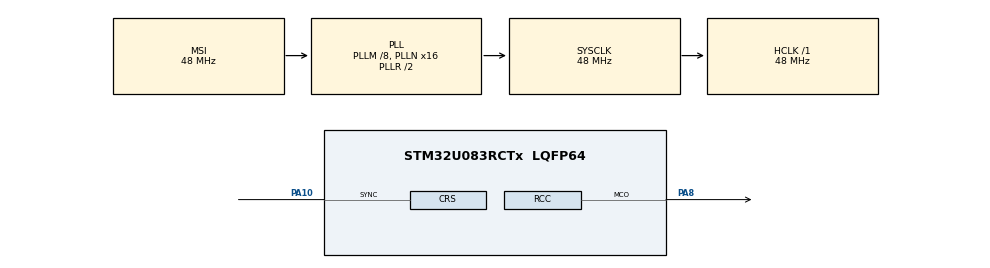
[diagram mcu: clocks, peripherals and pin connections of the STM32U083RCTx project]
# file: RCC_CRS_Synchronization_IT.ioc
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Mcu.Family=STM32U0
Mcu.Name=STM32U083RCTx
Mcu.Package=LQFP64
NVIC.PriorityGroup=NVIC_PRIORITYGROUP_2
PA10.Mode=CRS SYNC Source GPIO
PA10.Signal=CRS_SYNC
PA8.GPIO_Speed=GPIO_SPEED_FREQ_HIGH
PA8.Mode=Clock-out
PA8.Signal=RCC_MCO
PC14-OSC32_IN.Mode=LSE-External-Oscillator
PC14-OSC32_IN.Signal=RCC_OSC32_IN
PC15-OSC32_OUT.Mode=LSE-External-Oscillator
PC15-OSC32_OUT.Signal=RCC_OSC32_OUT
ProjectManager.HeapSize=0x200
ProjectManager.StackSize=0x400
ProjectManager.TargetToolchain=EWARM V9.20
RCC.ADCFreq_Value=48000000
RCC.AHBFreq_Value=48000000
RCC.CortexFreq_Value=48000000
RCC.HCLKFreq_Value=48000000
RCC.HSE_VALUE=4000000
RCC.HSI48_VALUE=48000000
RCC.HSI_VALUE=16000000
RCC.MSIClockRangeVal=RCC_MSIRANGE_11
RCC.MSI_VALUE=48000000
RCC.PLLM=RCC_PLLM_DIV8
RCC.PLLN=16
RCC.PLLSourceVirtual=RCC_PLLSOURCE_MSI
RCC.RCC_MCO1Source=RCC_MCO1SOURCE_HSI48
RCC.SYSCLKFreq_VALUE=48000000
RCC.SYSCLKSource=RCC_SYSCLKSOURCE_PLLCLK
RCC.USBFreq_Value=48000000
RCC.VCOOutputFreq_Value=96000000
VP_PWR_VS_SECSignals.Mode=Security/Privilege
board=custom

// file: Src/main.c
/* USER CODE BEGIN Header */
/**
  ******************************************************************************
  * @file    RCC/RCC_CRS_Synchronization_IT/Src/main.c
  * @author  MCD Application Team
  * @brief   This example describes how to use the RCC HAL API to configure the
  *          Clock Recovery System (CRS) in Interrupt mode.
  ******************************************************************************
  * @attention
  *
  * Copyright (c) 2023 STMicroelectronics.
  * All rights reserved.
  *
  * This software is licensed under terms that can be found in the LICENSE file
  * in the root directory of this software component.
  * If no LICENSE file comes with this software, it is provided AS-IS.
  *
  ******************************************************************************
  */
/* USER CODE END Header */
#include "main.h"

/* USER CODE BEGIN PD */
#define CRS_STATUS_INIT       0
#define CRS_STATUS_SYNCOK     1
#define CRS_STATUS_SYNCWARN   2
#define CRS_STATUS_SYNCMISS   3
#define CRS_STATUS_SYNCERR    4

#define CRS_MAX_FELIM_VALUE   0xFFU
/* USER CODE END PD */

/* USER CODE BEGIN PV */
RCC_CRSInitTypeDef CRSInitStruct = {0};
/* Variable to save SYNC status*/
__IO uint32_t CRSSyncStatus = CRS_STATUS_INIT;
/* USER CODE END PV */

void SystemClock_Config(void);
static void MX_GPIO_Init(void);
/* USER CODE BEGIN PFP */
static void CRS_Init(void);
/* USER CODE END PFP */

int main(void)
{

  /* USER CODE BEGIN 1 */
  RCC_CRSSynchroInfoTypeDef syncinfo = {0};
  /* USER CODE END 1 */

  /* MCU Configuration--------------------------------------------------------*/

  /* Reset of all peripherals, Initializes the Flash interface and the Systick. */
  HAL_Init();

  /* Configure the system clock */
  SystemClock_Config();

  /* Initialize all configured peripherals */
  MX_GPIO_Init();
  /* USER CODE BEGIN 2 */
  /* Configure LED4 */
  BSP_LED_Init(LED4);

  /* CRS initialization (enable HSI48 and LSE oscillators and then enable CRS clock */
  /* Enable RCC_CRS interrupt */
  CRS_Init();

  /* HSI48 Synchronization without synchronization frequency (source set to GPIO */
  /* which is not configured)*/
  CRSInitStruct.Prescaler             = RCC_CRS_SYNC_DIV1;
  CRSInitStruct.Source                = RCC_CRS_SYNC_SOURCE_GPIO;
  CRSInitStruct.Polarity              = RCC_CRS_SYNC_POLARITY_FALLING;
  /* F(LSE)=32.768kHz then Reload=(f(Target)/f(LSE))-1= 0x5B7*/
  CRSInitStruct.ReloadValue           = __HAL_RCC_CRS_RELOADVALUE_CALCULATE(HSI48_VALUE, LSE_VALUE);
  /* Felim value calculated like this FELIM = (fTARGET / fSYNC) * STEP[%] / 100% / 2 with STEP=0.14% then FELIM = 2 */
  CRSInitStruct.ErrorLimitValue       = 2;
  /* Change the HSI trimming value to see the automatic calibration performed by CRS */
  CRSInitStruct.HSI48CalibrationValue = 0x00;

  /* Start automatic synchronization*/
  HAL_RCCEx_CRSConfig(&CRSInitStruct);

  /* Enable RCC_CRS interrupts */
  __HAL_RCC_CRS_ENABLE_IT(RCC_CRS_IT_SYNCOK | RCC_CRS_IT_SYNCWARN | RCC_CRS_IT_ERR | RCC_CRS_IT_ESYNC);

  /* Simulate a SYNC EVENT which will raise a SYNC_MISS EVENT */
  HAL_RCCEx_CRSSoftwareSynchronizationGenerate();
  /* USER CODE END 2 */

  /* Infinite loop */
  while (1)
  {

    /* USER CODE BEGIN 3 */
    switch (CRSSyncStatus)
    {
      case CRS_STATUS_SYNCOK:
        /* Power on LED4 */
        BSP_LED_On(LED4);
        /* For visual comfort on LED4 apply delay */
        HAL_Delay(1000);
        /* Enable CRS SYNCWARN interrupt (in case it goes out of sync) */
        __HAL_RCC_CRS_ENABLE_IT(RCC_CRS_IT_SYNCWARN);
        break;

      case CRS_STATUS_SYNCMISS:
        /* Power off LED4 */
        BSP_LED_Off(LED4);
        /* Perform a new configuration to LSE when SYNC MISS is detected. */
        /* For visual comfort on LED4 apply delay before new configuration */
        HAL_Delay(1000);

        /* Retrieve synchronization information */
        HAL_RCCEx_CRSGetSynchronizationInfo(&syncinfo);

        /* Change source to LSE and restart synchronization if necessary */
        if (CRSInitStruct.Source != RCC_CRS_SYNC_SOURCE_LSE)
        {
          CRSInitStruct.Source = RCC_CRS_SYNC_SOURCE_LSE;
          HAL_RCCEx_CRSConfig(&CRSInitStruct);

          /* Enable CRS interrupts after new CRS configuration */
          __HAL_RCC_CRS_ENABLE_IT(RCC_CRS_IT_SYNCOK | RCC_CRS_IT_SYNCWARN | RCC_CRS_IT_ERR | RCC_CRS_IT_ESYNC);
        }
        else
        {
          /* Enable RCC_CRS SYNCOK interrupt */
          __HAL_RCC_CRS_ENABLE_IT(RCC_CRS_IT_SYNCOK);
        }
        break;

      case CRS_STATUS_SYNCWARN:
        /* Toggle LED4 when SYNC WARN is detected. */
        BSP_LED_On(LED4);
        HAL_Delay(100);
        BSP_LED_Off(LED4);
        HAL_Delay(100);
        BSP_LED_On(LED4);
        HAL_Delay(100);
        BSP_LED_Off(LED4);
        HAL_Delay(100);
        BSP_LED_On(LED4);
        HAL_Delay(100);
        BSP_LED_Off(LED4);
        /* Increase tolerance (FELIM value) until no more warning */
        CRSInitStruct.ErrorLimitValue += 1;
        /* Max value for FELIM has been reached? */
        if (CRSInitStruct.ErrorLimitValue > CRS_MAX_FELIM_VALUE)
        {
          Error_Handler();
        }
        HAL_RCCEx_CRSConfig(&CRSInitStruct);
        /* Enable CRS interrupts after new CRS configuration */
        __HAL_RCC_CRS_ENABLE_IT(RCC_CRS_IT_SYNCOK | RCC_CRS_IT_SYNCWARN | RCC_CRS_IT_ERR | RCC_CRS_IT_ESYNC);
        break;

      case CRS_STATUS_SYNCERR:
        /* Power off LED4 */
        BSP_LED_Off(LED4);
        break;

      default:
        break;
    }
  }
  /* USER CODE END 3 */
}

void SystemClock_Config(void)
{
  RCC_OscInitTypeDef RCC_OscInitStruct = {0};
  RCC_ClkInitTypeDef RCC_ClkInitStruct = {0};
  RCC_CRSInitTypeDef RCC_CRSInitStruct = {0};

  /** Configure the main internal regulator output voltage
  */
  HAL_PWREx_ControlVoltageScaling(PWR_REGULATOR_VOLTAGE_SCALE1);

  /** Initializes the RCC Oscillators according to the specified parameters
  * in the RCC_OscInitTypeDef structure.
  */
  RCC_OscInitStruct.OscillatorType = RCC_OSCILLATORTYPE_HSI48|RCC_OSCILLATORTYPE_MSI;
  RCC_OscInitStruct.MSIState = RCC_MSI_ON;
  RCC_OscInitStruct.MSICalibrationValue = RCC_MSICALIBRATION_DEFAULT;
  RCC_OscInitStruct.MSIClockRange = RCC_MSIRANGE_11;
  RCC_OscInitStruct.HSI48State = RCC_HSI48_ON;
  RCC_OscInitStruct.PLL.PLLState = RCC_PLL_ON;
  RCC_OscInitStruct.PLL.PLLSource = RCC_PLLSOURCE_MSI;
  RCC_OscInitStruct.PLL.PLLM = RCC_PLLM_DIV8;
  RCC_OscInitStruct.PLL.PLLN = 16;
  RCC_OscInitStruct.PLL.PLLP = RCC_PLLP_DIV2;
  RCC_OscInitStruct.PLL.PLLQ = RCC_PLLQ_DIV2;
  RCC_OscInitStruct.PLL.PLLR = RCC_PLLR_DIV2;
  if (HAL_RCC_OscConfig(&RCC_OscInitStruct) != HAL_OK)
  {
    Error_Handler();
  }

  /** Initializes the CPU, AHB and APB buses clocks
  */
  RCC_ClkInitStruct.ClockType = RCC_CLOCKTYPE_HCLK|RCC_CLOCKTYPE_SYSCLK
                              |RCC_CLOCKTYPE_PCLK1;
  RCC_ClkInitStruct.SYSCLKSource = RCC_SYSCLKSOURCE_PLLCLK;
  RCC_ClkInitStruct.AHBCLKDivider = RCC_SYSCLK_DIV1;
  RCC_ClkInitStruct.APB1CLKDivider = RCC_HCLK_DIV1;

  if (HAL_RCC_ClockConfig(&RCC_ClkInitStruct, FLASH_LATENCY_1) != HAL_OK)
  {
    Error_Handler();
  }

  /** Enable the CRS clock
  */
  __HAL_RCC_CRS_CLK_ENABLE();

  /** Configures CRS
  */
  RCC_CRSInitStruct.Prescaler = RCC_CRS_SYNC_DIV1;
  RCC_CRSInitStruct.Source = RCC_CRS_SYNC_SOURCE_GPIO;
  RCC_CRSInitStruct.Polarity = RCC_CRS_SYNC_POLARITY_RISING;
  RCC_CRSInitStruct.ReloadValue = __HAL_RCC_CRS_RELOADVALUE_CALCULATE(48000000,1);
  RCC_CRSInitStruct.ErrorLimitValue = 34;
  RCC_CRSInitStruct.HSI48CalibrationValue = 32;

  HAL_RCCEx_CRSConfig(&RCC_CRSInitStruct);
  HAL_RCC_MCOConfig(RCC_MCO1, RCC_MCO1SOURCE_HSI48, RCC_MCO1DIV_1);
}

static void MX_GPIO_Init(void)
{
  GPIO_InitTypeDef GPIO_InitStruct = {0};

  /* GPIO Ports Clock Enable */
  __HAL_RCC_GPIOC_CLK_ENABLE();
  __HAL_RCC_GPIOA_CLK_ENABLE();

  /*Configure GPIO pin : PA8 */
  GPIO_InitStruct.Pin = GPIO_PIN_8;
  GPIO_InitStruct.Mode = GPIO_MODE_AF_PP;
  GPIO_InitStruct.Pull = GPIO_NOPULL;
  GPIO_InitStruct.Speed = GPIO_SPEED_FREQ_HIGH;
  GPIO_InitStruct.Alternate = GPIO_AF0_MCO;
  HAL_GPIO_Init(GPIOA, &GPIO_InitStruct);

  /*Configure GPIO pin : PA10 */
  GPIO_InitStruct.Pin = GPIO_PIN_10;
  GPIO_InitStruct.Mode = GPIO_MODE_AF_PP;
  GPIO_InitStruct.Pull = GPIO_NOPULL;
  GPIO_InitStruct.Speed = GPIO_SPEED_FREQ_LOW;
  GPIO_InitStruct.Alternate = GPIO_AF10_CRS;
  HAL_GPIO_Init(GPIOA, &GPIO_InitStruct);

}

/* USER CODE BEGIN 4 */
/**
  * @brief  This function initializes the clock configuration for CRS.
  * @param  None
  * @retval None
  */
static void CRS_Init(void)
{
  RCC_OscInitTypeDef RCC_OscInitStruct = {0};

  HAL_RCC_GetOscConfig(&RCC_OscInitStruct);

  /* Enable HSI48 and LSE Oscillator*/
  RCC_OscInitStruct.OscillatorType = RCC_OSCILLATORTYPE_HSI48 | RCC_OSCILLATORTYPE_LSE;
  RCC_OscInitStruct.HSI48State     = RCC_HSI48_ON;
  RCC_OscInitStruct.LSEState       = RCC_LSE_ON;
  RCC_OscInitStruct.PLL.PLLState   = RCC_PLL_NONE;
  if (HAL_RCC_OscConfig(&RCC_OscInitStruct) != HAL_OK)
  {
    Error_Handler();
  }

  /* Enable CRS clock*/
  __HAL_RCC_CRS_CLK_ENABLE();

  /* Enable and set RCC_CRS interrupt*/
  HAL_NVIC_SetPriority(RCC_CRS_IRQn, 0x03, 0x00);
  HAL_NVIC_EnableIRQ(RCC_CRS_IRQn);

  /* Output HSI48 MCO pin(PA8) */
  HAL_RCC_MCOConfig(RCC_MCO1, RCC_MCO1SOURCE_HSI48, RCC_MCO1DIV_1);
}

/**
  * @brief  RCCEx Clock Recovery System SYNCOK interrupt callback.
  * @retval none
  */
void HAL_RCCEx_CRS_SyncOkCallback(void)
{
  CRSSyncStatus = CRS_STATUS_SYNCOK;

  /* Disable CRS SYNCOK interrupt since synchronization succeeded */
  __HAL_RCC_CRS_DISABLE_IT(RCC_CRS_IT_SYNCOK);
}

/**
  * @brief  RCCEx Clock Recovery System SYNCWARN interrupt callback.
  * @retval none
  */
void HAL_RCCEx_CRS_SyncWarnCallback(void)
{
  CRSSyncStatus = CRS_STATUS_SYNCWARN;
  /* Disable temporary CRS SYNCWARN interrupt to let the main loop to be execute */
  __HAL_RCC_CRS_DISABLE_IT(RCC_CRS_IT_SYNCWARN);
}

/**
  * @brief  RCCEx Clock Recovery System Expected SYNC interrupt callback.
  * @retval none
  */
void HAL_RCCEx_CRS_ExpectedSyncCallback(void)
{
}

/**
  * @brief  RCCEx Clock Recovery System Error interrupt callback.
  * @param  Combination of Error status.
  *         This parameter can be a combination of the following values:
  *           @arg @ref RCC_CRS_SYNCERR
  *           @arg @ref RCC_CRS_SYNCMISS
  *           @arg @ref RCC_CRS_TRIMOVF
  * @retval none
  */
void HAL_RCCEx_CRS_ErrorCallback(uint32_t Error)
{
  if ((Error & RCC_CRS_SYNCMISS) != RESET)
  {
    CRSSyncStatus = CRS_STATUS_SYNCMISS;
  }
  else if ((Error & RCC_CRS_SYNCERR) != RESET)
  {
    CRSSyncStatus = CRS_STATUS_SYNCERR;
  }
}
/* USER CODE END 4 */

void Error_Handler(void)
{
  /* USER CODE BEGIN Error_Handler_Debug */
  /* LED4 is slowly blinking (1 sec. period) */
  while (1)
  {
    BSP_LED_Toggle(LED4);
    HAL_Delay(1000);
  }
  /* USER CODE END Error_Handler_Debug */
}
